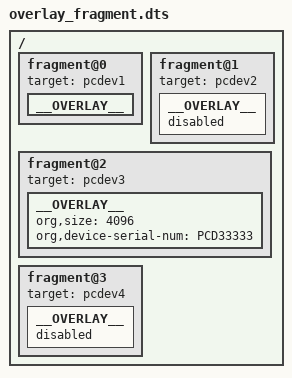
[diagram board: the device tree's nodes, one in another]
/dts-v1/;
/plugin/;

/{
	fragment@0 {
		target = <&pcdev1>;
		__OVERLAY__ {
			status = "ok";
		};
	};
	fragment@1 {
		target = <&pcdev2>;
		__OVERLAY__ {
			status = "disabled";
		};
	};
	fragment@2 {
		target = <&pcdev3>;
		__OVERLAY__ {
			status = "ok";
			org,size = <4096>;
			org,device-serial-num="PCD33333";
		};
	};
	fragment@3 {
		target = <&pcdev4>;
		__OVERLAY__{
			status = "disabled";
		};
	};
};
